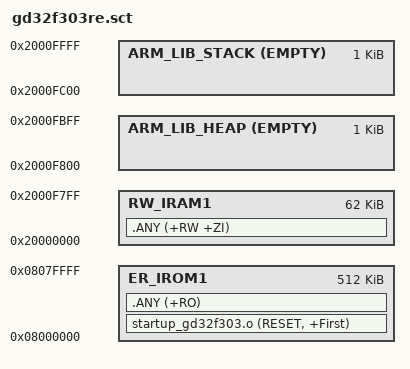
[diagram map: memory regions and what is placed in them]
LR_IROM1 0x08000000 0x00080000
{
    ER_IROM1 0x08000000 0x00080000
    {
        startup_gd32f303.o (RESET, +First)
        .ANY (+RO)
    }
    RW_IRAM1 0x20000000 0x0000F800
    {
        .ANY (+RW +ZI)
    }
    ARM_LIB_HEAP 0x2000F800 EMPTY 0x00000400
    {
    }
    ARM_LIB_STACK 0x20010000 EMPTY -0x00000400
    {
    }
}
